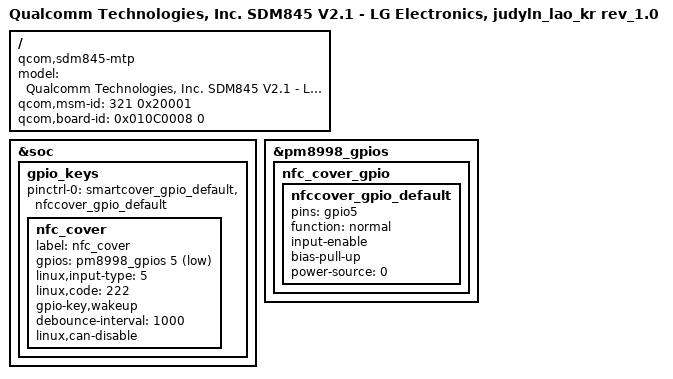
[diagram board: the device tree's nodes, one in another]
/* Copyright (c) 2017, The Linux Foundation. All rights reserved.
 *
 * This program is free software; you can redistribute it and/or modify
 * it under the terms of the GNU General Public License version 2 and
 * only version 2 as published by the Free Software Foundation.
 *
 * This program is distributed in the hope that it will be useful,
 * but WITHOUT ANY WARRANTY; without even the implied warranty of
 * MERCHANTABILITY or FITNESS FOR A PARTICULAR PURPOSE.  See the
 * GNU General Public License for more details.
 */


/dts-v1/;
/plugin/;

#include "sdm845-judyln_lao_com.dtsi"
#include "sdm845-judyln_lao_com-tdmb_rev-a.dtsi"
#include "sdm845-judy_common-fingerprint_rev-a.dtsi"
#include "../sdm845-judy_common/sdm845-judy_common-usb_ext_pulldown_ctrl.dtsi"
#include "sdm845-judyln_lao_com-sound_kr_rev-a.dtsi"

/ {
	model = "Qualcomm Technologies, Inc. SDM845 V2.1 - LG Electronics, judyln_lao_kr rev_1.0";
	compatible = "qcom,sdm845-mtp", "qcom,sdm845", "qcom,mtp";
	qcom,msm-id = <321 0x20001>;
	qcom,board-id = <0x010C0008 0>;
};

&soc {
	gpio_keys {
		pinctrl-0 = <&smartcover_gpio_default &nfccover_gpio_default>;

		nfc_cover {
			label = "nfc_cover";
			gpios = <&pm8998_gpios 5 GPIO_ACTIVE_LOW>;
			linux,input-type = <5>;
			linux,code = <222>;
			gpio-key,wakeup;
			debounce-interval = <1000>;
			linux,can-disable;
		};
	};
};

&pm8998_gpios {
	nfc_cover_gpio {
		 nfccover_gpio_default: nfccover_gpio_default {
			pins = "gpio5";
			function = "normal";
			input-enable;
			bias-pull-up;
			power-source = <0>;
		};
	};
};
